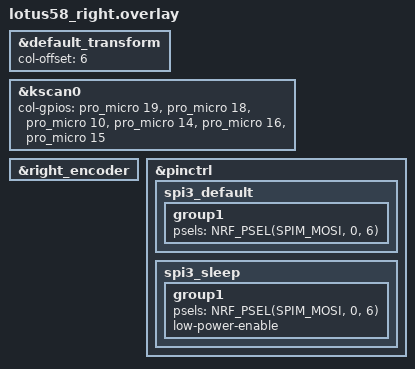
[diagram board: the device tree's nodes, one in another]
/*
 * Copyright (c) 2022 The ZMK Contributors
 *
 * SPDX-License-Identifier: MIT
 */

#include "lotus58.dtsi"
#include <dt-bindings/led/led.h>

&default_transform {
    col-offset = <6>;
};

&kscan0 {
    col-gpios
        = <&pro_micro 19 GPIO_ACTIVE_HIGH>
        , <&pro_micro 18 GPIO_ACTIVE_HIGH>
        , <&pro_micro 10 GPIO_ACTIVE_HIGH>
        , <&pro_micro 14 GPIO_ACTIVE_HIGH>
        , <&pro_micro 16 GPIO_ACTIVE_HIGH>
        , <&pro_micro 15 GPIO_ACTIVE_HIGH>
        ;
};

&right_encoder {
    status = "okay";
};

&pinctrl {
    spi3_default: spi3_default {
        group1 {
            psels = <NRF_PSEL(SPIM_MOSI, 0, 6)>;
        };
    };

    spi3_sleep: spi3_sleep {
        group1 {
            psels = <NRF_PSEL(SPIM_MOSI, 0, 6)>;
            low-power-enable;
        };
    };
};
// Defined node
